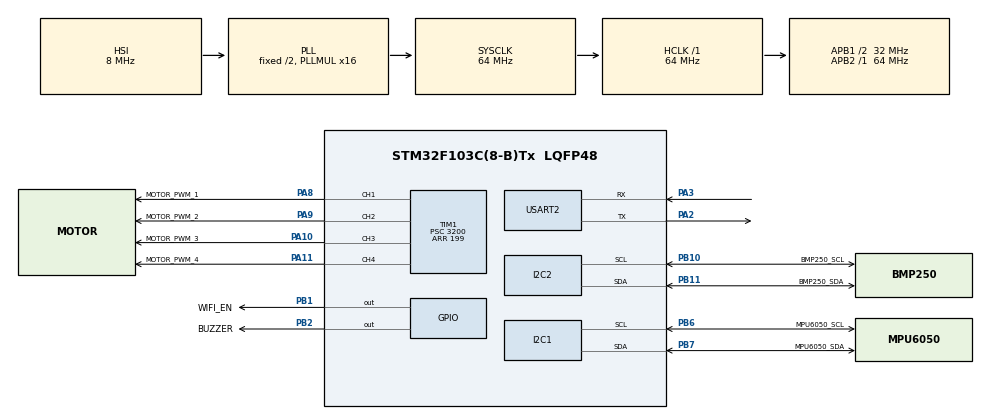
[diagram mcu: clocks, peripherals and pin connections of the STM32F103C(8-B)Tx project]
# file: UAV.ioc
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Mcu.Family=STM32F1
Mcu.Name=STM32F103C(8-B)Tx
Mcu.Package=LQFP48
NVIC.PriorityGroup=NVIC_PRIORITYGROUP_4
PA10.GPIO_Label=MOTOR_PWM_3
PA10.Signal=S_TIM1_CH3
PA11.GPIO_Label=MOTOR_PWM_4
PA11.Signal=S_TIM1_CH4
PA13.Mode=Serial_Wire
PA13.Signal=SYS_JTMS-SWDIO
PA14.Mode=Serial_Wire
PA14.Signal=SYS_JTCK-SWCLK
PA2.Mode=Asynchronous
PA2.Signal=USART2_TX
PA3.Mode=Asynchronous
PA3.Signal=USART2_RX
PA8.GPIO_Label=MOTOR_PWM_1
PA8.Signal=S_TIM1_CH1
PA9.GPIO_Label=MOTOR_PWM_2
PA9.Signal=S_TIM1_CH2
PB1.GPIO_Label=WIFI_EN
PB1.PinState=GPIO_PIN_SET
PB1.Signal=GPIO_Output
PB10.GPIO_Label=BMP250_SCL
PB10.Mode=I2C
PB10.Signal=I2C2_SCL
PB11.GPIO_Label=BMP250_SDA
PB11.Mode=I2C
PB11.Signal=I2C2_SDA
PB2.GPIO_Label=BUZZER
PB2.PinState=GPIO_PIN_SET
PB2.Signal=GPIO_Output
PB6.GPIO_Label=MPU6050_SCL
PB6.Mode=I2C
PB6.Signal=I2C1_SCL
PB7.GPIO_Label=MPU6050_SDA
PB7.Mode=I2C
PB7.Signal=I2C1_SDA
ProjectManager.HeapSize=0x200
ProjectManager.StackSize=0x400
ProjectManager.TargetToolchain=MDK-ARM V5.27
RCC.AHBFreq_Value=64000000
RCC.APB1CLKDivider=RCC_HCLK_DIV2
RCC.APB1Freq_Value=32000000
RCC.APB1TimFreq_Value=64000000
RCC.APB2Freq_Value=64000000
RCC.APB2TimFreq_Value=64000000
RCC.HCLKFreq_Value=64000000
RCC.PLLMUL=RCC_PLL_MUL16
RCC.SYSCLKFreq_VALUE=64000000
RCC.SYSCLKSource=RCC_SYSCLKSOURCE_PLLCLK
RCC.USBFreq_Value=64000000
SH.S_TIM1_CH1.0=TIM1_CH1,PWM Generation1 CH1
SH.S_TIM1_CH2.0=TIM1_CH2,PWM Generation2 CH2
SH.S_TIM1_CH3.0=TIM1_CH3,PWM Generation3 CH3
SH.S_TIM1_CH4.0=TIM1_CH4,PWM Generation4 CH4
TIM1.Channel-PWM\ Generation1\ CH1=TIM_CHANNEL_1
TIM1.Channel-PWM\ Generation2\ CH2=TIM_CHANNEL_2
TIM1.Channel-PWM\ Generation3\ CH3=TIM_CHANNEL_3
TIM1.Channel-PWM\ Generation4\ CH4=TIM_CHANNEL_4
TIM1.Period=199
TIM1.Prescaler=3200
USART2.VirtualMode=VM_ASYNC
board=custom

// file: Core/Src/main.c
/* USER CODE BEGIN Header */
/**
 ******************************************************************************
 * @file           : main.c
 * @brief          : Main program body
 ******************************************************************************
 * @attention
 *
 * Copyright (c) 2024 STMicroelectronics.
 * All rights reserved.
 *
 * This software is licensed under terms that can be found in the LICENSE file
 * in the root directory of this software component.
 * If no LICENSE file comes with this software, it is provided AS-IS.
 *
 ******************************************************************************
 */
/* USER CODE END Header */
#include "main.h"
#include "i2c.h"
#include "tim.h"
#include "usart.h"
#include "gpio.h"
#include "pid.h"
#include "motor.h"
#include "mpu6050.h"
#include "inv_mpu.h"
#include "inv_mpu_dmp_motion_driver.h"
#include <stdio.h>

/* USER CODE BEGIN PV */
float roll, pitch, yaw;
/* USER CODE END PV */

void SystemClock_Config(void);

int main(void)
{

	/* MCU Configuration--------------------------------------------------------*/

	/* Reset of all peripherals, Initializes the Flash interface and the Systick. */
	HAL_Init();

	/* Configure the system clock */
	SystemClock_Config();

	/* Initialize all configured peripherals */
	MX_GPIO_Init();
	MX_I2C1_Init();
	MX_I2C2_Init();
	MX_TIM1_Init();
	MX_USART2_UART_Init();

	HAL_TIM_PWM_Start(&htim1, TIM_CHANNEL_1);
	HAL_TIM_PWM_Start(&htim1, TIM_CHANNEL_2);
	HAL_TIM_PWM_Start(&htim1, TIM_CHANNEL_3);
	HAL_TIM_PWM_Start(&htim1, TIM_CHANNEL_4);

	PID pid_roll;
	PID pid_pitch;

	PID_Init(&pid_roll, 20.0, 0, 0, 100, 1000);
	PID_Init(&pid_pitch, 20.0, 0, 0, 100, 1000);

	/* Infinite loop */
	/* USER CODE BEGIN WHILE */
	printf("-- Mpu6050 Project Start -- \r\n");
	HAL_Delay(1000);
	/*
	 *DMP初始化，
	 *好的TOO！！！
	 */
	while (mpu_dmp_init())
	{
		HAL_Delay(200);
	}
	printf("Successfully initialized!\r\n");
	/*
	 *iic读取器件ID ，测试IIC能否使用，测试一下
	 *好的TOO！！
	 */
	printf("Ready to read the ID\r\n");
	uint8_t recv = 0x00;
	HAL_I2C_Mem_Read(&hi2c1, (0x68 << 1), 0x75, I2C_MEMADD_SIZE_8BIT, &recv, 1, 0xfff);
	if (recv == 0x68)
	{
		printf("mpu6050 ID Read: OK at 0x68\r\n"); // 成功
	}
	else
	{
		printf("Err mpu id:0x%x\r\n", recv); // 失败
	}
	/* USER CODE END 2 */

	/* Infinite loop */
	/* USER CODE BEGIN WHILE */
	while (1)
	{
		/* USER CODE END WHILE */
		while (mpu_dmp_get_data(&pitch, &roll, &yaw) != 0)
			;									  // 获取欧拉角的参数
		printf("%f,%f,%f\r\n", pitch, roll, yaw); // 打印到串口上

		HAL_Delay(500);
	}
}

void SystemClock_Config(void)
{
	RCC_OscInitTypeDef RCC_OscInitStruct = {0};
	RCC_ClkInitTypeDef RCC_ClkInitStruct = {0};

	/** Initializes the RCC Oscillators according to the specified parameters
	 * in the RCC_OscInitTypeDef structure.
	 */
	RCC_OscInitStruct.OscillatorType = RCC_OSCILLATORTYPE_HSI;
	RCC_OscInitStruct.HSIState = RCC_HSI_ON;
	RCC_OscInitStruct.HSICalibrationValue = RCC_HSICALIBRATION_DEFAULT;
	RCC_OscInitStruct.PLL.PLLState = RCC_PLL_ON;
	RCC_OscInitStruct.PLL.PLLSource = RCC_PLLSOURCE_HSI_DIV2;
	RCC_OscInitStruct.PLL.PLLMUL = RCC_PLL_MUL16;
	if (HAL_RCC_OscConfig(&RCC_OscInitStruct) != HAL_OK)
	{
		Error_Handler();
	}

	/** Initializes the CPU, AHB and APB buses clocks
	 */
	RCC_ClkInitStruct.ClockType = RCC_CLOCKTYPE_HCLK | RCC_CLOCKTYPE_SYSCLK | RCC_CLOCKTYPE_PCLK1 | RCC_CLOCKTYPE_PCLK2;
	RCC_ClkInitStruct.SYSCLKSource = RCC_SYSCLKSOURCE_PLLCLK;
	RCC_ClkInitStruct.AHBCLKDivider = RCC_SYSCLK_DIV1;
	RCC_ClkInitStruct.APB1CLKDivider = RCC_HCLK_DIV2;
	RCC_ClkInitStruct.APB2CLKDivider = RCC_HCLK_DIV1;

	if (HAL_RCC_ClockConfig(&RCC_ClkInitStruct, FLASH_LATENCY_2) != HAL_OK)
	{
		Error_Handler();
	}
}

void Error_Handler(void)
{
	__disable_irq();
	while (1)
	{
	}
}
